# SN32F420 register map
Vendor: SONiX Technology Co., Ltd.; Series: SN32F420; File version: 1.00
CPU: CM0 r0p0, little endian, no MPU, no FPU, 2 interrupt priority bits
Registers are 32-bit, read-write, reset 0x0 unless marked. A register's access mark holds for its fields unless they carry their own. Offsets are from the block's base; [hi:lo] are bit positions.

## SN_CMP — Comparator
Base 0x40028000
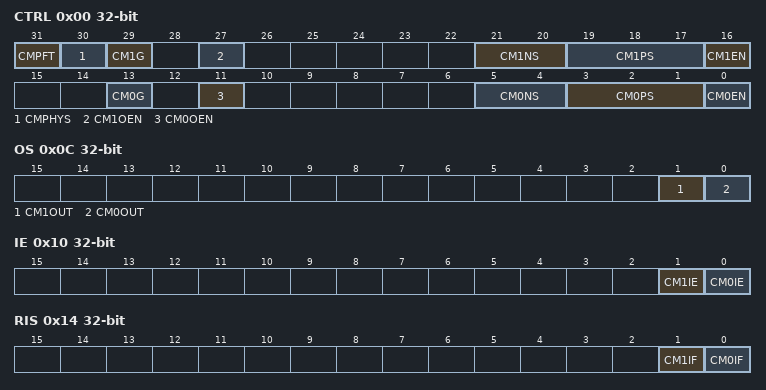
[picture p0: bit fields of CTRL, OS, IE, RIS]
0x00 CTRL — Offset:0x00 CMP Control register
  [31] CMPFT — CMP fast comparison enable bit
    0=Disable (Low Power mode); 1=Enable (Normal mode)
  [30] CMPHYS — CMP hysteresis selection bit
    0=0mV; 1=20mV
  [29] CM1G — CMP1 interrupt trigger direction control bit
    0=Falling range trigger (CMP1 output status is from high to low as V+ is less than V-); 1=Rising edge trigger (CMP1 output status is from low to high as V+ is more than V-)
  [27] CM1OEN — CMP1 Output pin control bits
    0=Disable CM1O; 1=Enable CM1O
  [21:20] CM1NS — CMP1 Negative input pin
    0=CM1N0 (CM1N0 is negative input pin); 1=CM1N1 (CM1N1 is negative input pin); 2=CM1N2 (CM1N2 is negative input pin); 3=DAC (DAC. CM1N0/CM1N1/CM1N2 pins are GPIO mode)
  [19:17] CM1PS — CMP1 Positive input selection bits
    0=DAC (DAC. CM1P0/CM1P1/CM1P2 pins are GPIO mode); 1=CM1P0 (CM1P0 is positive input pin); 2=CM1P1 (CM1P1 is positive input pin); 3=CM1P2 (CM1P2 is positive input pin); 4=OPA_VOP (OPA_VOP. CM1P0/CM1P1/CM1P2 pins are GPIO mode); 5=OPA_IP (OPA_IP. CM1P0/CM1P1/CM1P2 pins are GPIO mode)
  [16] CM1EN — CMP1 Enable bit
    0=Disable CMP1; 1=Enable CMP1
  [13] CM0G — CMP0 interrupt trigger direction control bit
    0=Falling range trigger (CMP0 output status is from high to low as V+ is less than V-); 1=Rising edge trigger (CMP0 output status is from low to high as V+ is more than V-)
  [11] CM0OEN — CMP0 Output pin control bits
    0=Disable CM0O; 1=Enable CM0O
  [5:4] CM0NS — CMP0 Negative input pin
    0=CM0N0 (CM0N0 is negative input pin); 1=CM0N1 (CM0N1 is negative input pin); 2=CM0N2 (CM0N2 is negative input pin); 3=DAC (DAC. CM0N0/CM0N1/CM0N2 pins are GPIO mode)
  [3:1] CM0PS — CMP0 Positive input selection bits
    0=DAC (DAC. CM0P0/CM0P1/CM0P2 pins are GPIO mode); 1=CM0P0 (CM0P0 is positive input pin); 2=CM0P1 (CM0P1 is positive input pin); 3=CM0P2 (CM0P2 is positive input pin); 4=OPA_VOP (OPA_VOP. CM0P0/CM0P1/CM0P2 pins are GPIO mode); 5=OPA_IP (OPA_IP. CM0P0/CM0P1/CM0P2 pins are GPIO mode)
  [0] CM0EN — CMP0 Enable bit
    0=Disable CMP0; 1=Enable CMP0
0x0C OS ro — Offset:0xC CMP Output Status register
  [1] CM1OUT — CMP1 Output flag bit
    0=CMP1 V+ is less than V- (V1+ is less than V1-); 1=CMP1 V+ is more than V- (V1+ is more than V1- voltage)
  [0] CM0OUT — CMP0 Output flag bit
    0=CMP0 V+ is less than V- (V0+ is less than V0-); 1=CMP0 V+ is more than V- (V0+ is more than V0-)
0x10 IE — Offset:0x10 CMP Interrupt Enable register
  [1] CM1IE — CMP1 interrupt enable
    0=Disable CMP1 interrupt; 1=Enable CMP1 interrupt
  [0] CM0IE — CMP0 interrupt enable
    0=Disable CMP0 interrupt; 1=Enable CMP0 interrupt
0x14 RIS ro — Offset:0x14 CMP Raw Interrupt Status register
  [1] CM1IF — CMP1 raw interrupt flag
    0=None (No interrupt on CMP1); 1=Met interrupt requirements (Interrupt requirements met on CMP1)
  [0] CM0IF — CMP0 raw interrupt flag
    0=None (No interrupt on CMP0); 1=Met interrupt requirements (Interrupt requirements met on CMP0)
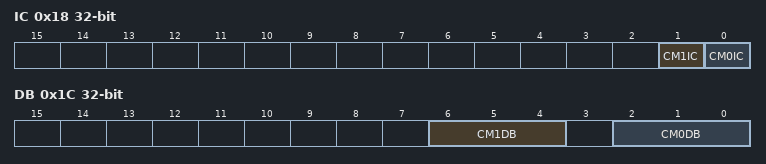
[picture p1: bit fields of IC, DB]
0x18 IC wo — Offset:0x18 CMP Interrupt Clear register
  [1] CM1IC — CMP1 interrupt flag clear bit
    0=None (No effect); 1=Clear CMP1 interrupt flag
  [0] CM0IC — CMP0 interrupt flag clear bit
    0=None (No effect); 1=Clear CMP0 interrupt flag
0x1C DB — Offset:0x1C CMP Interrupt Clear register
  [6:4] CM1DB — Count for CMP1 output debounce time
    0=000b (No CMP1 output debounce time); 1=001b (CMP1 output debounce time=2*CMP1_PCLK); 2=010b (CMP1 output debounce time=4*CMP1_PCLK); 3=011b (CMP1 output debounce time=8*CMP1_PCLK); 4=100b (CMP1 output debounce time=16*CMP1_PCLK); 5=101b (CMP1 output debounce time=32*CMP1_PCLK); 6=110b (CMP1 output debounce time=64*CMP1_PCLK); 7=111b (CMP1 output debounce time=128*CMP1_PCLK)
  [2:0] CM0DB — Count for CMP0 output debounce time
    0=000b (No CMP0 output debounce time); 1=001b (CMP0 output debounce time=2*CMP0_PCLK); 2=010b (CMP0 output debounce time=4*CMP0_PCLK); 3=011b (CMP0 output debounce time=8*CMP0_PCLK); 4=100b (CMP0 output debounce time=16*CMP0_PCLK); 5=101b (CMP0 output debounce time=32*CMP0_PCLK); 6=110b (CMP0 output debounce time=64*CMP0_PCLK); 7=111b (CMP0 output debounce time=128*CMP0_PCLK)
